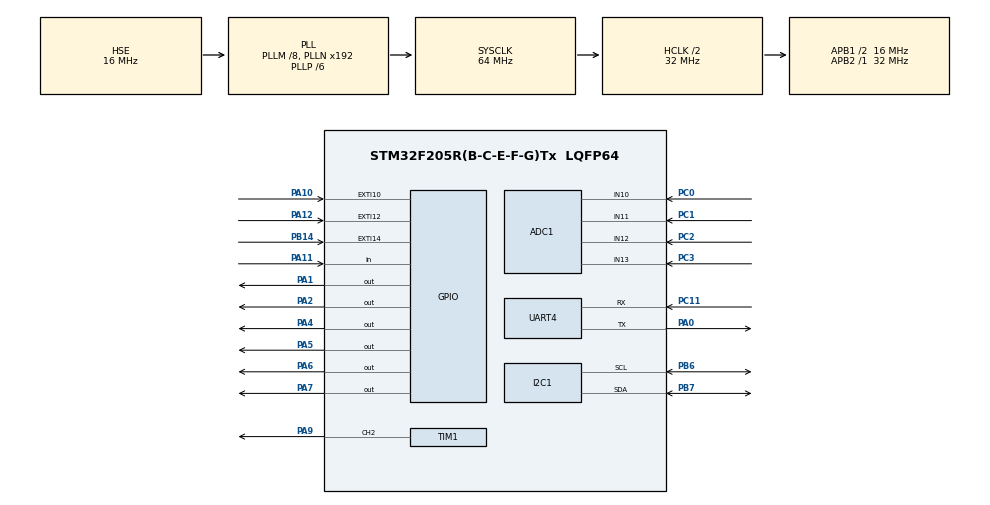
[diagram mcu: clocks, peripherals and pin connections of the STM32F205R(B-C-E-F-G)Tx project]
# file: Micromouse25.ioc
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ADC1.Channel-1\#ChannelRegularConversion=ADC_CHANNEL_10
ADC1.NbrOfConversionFlag=1
ADC1.Rank-1\#ChannelRegularConversion=1
ADC1.SamplingTime-1\#ChannelRegularConversion=ADC_SAMPLETIME_3CYCLES
ADC1.master=1
Mcu.Family=STM32F2
Mcu.Name=STM32F205R(B-C-E-F-G)Tx
Mcu.Package=LQFP64
NVIC.EXTI15_10_IRQn=true\:0\:0\:false\:false\:true\:true\:true\:true
NVIC.PriorityGroup=NVIC_PRIORITYGROUP_4
PA0-WKUP.Mode=Asynchronous
PA0-WKUP.Signal=UART4_TX
PA1.Signal=GPIO_Output
PA10.Signal=GPXTI10
PA11.Signal=GPIO_Input
PA12.Signal=GPXTI12
PA13.Mode=Serial_Wire
PA13.Signal=SYS_JTMS-SWDIO
PA14.Mode=Serial_Wire
PA14.Signal=SYS_JTCK-SWCLK
PA2.Signal=GPIO_Output
PA4.Signal=GPIO_Output
PA5.Signal=GPIO_Output
PA6.Signal=GPIO_Output
PA7.Signal=GPIO_Output
PA9.Signal=S_TIM1_CH2
PB14.Signal=GPXTI14
PB6.Mode=I2C
PB6.Signal=I2C1_SCL
PB7.Mode=I2C
PB7.Signal=I2C1_SDA
PC0.Signal=ADCx_IN10
PC1.Signal=ADCx_IN11
PC11.Mode=Asynchronous
PC11.Signal=UART4_RX
PC2.Signal=ADCx_IN12
PC3.Signal=ADCx_IN13
PH0-OSC_IN.Mode=HSE-External-Oscillator
PH0-OSC_IN.Signal=RCC_OSC_IN
PH1-OSC_OUT.Mode=HSE-External-Oscillator
PH1-OSC_OUT.Signal=RCC_OSC_OUT
ProjectManager.HeapSize=0x200
ProjectManager.StackSize=0x400
ProjectManager.TargetToolchain=STM32CubeIDE
RCC.48MHZClocksFreq_Value=96000000
RCC.AHBCLKDivider=RCC_SYSCLK_DIV2
RCC.AHBFreq_Value=32000000
RCC.APB1CLKDivider=RCC_HCLK_DIV2
RCC.APB1Freq_Value=16000000
RCC.APB1TimFreq_Value=32000000
RCC.APB2Freq_Value=32000000
RCC.APB2TimFreq_Value=32000000
RCC.CortexFreq_Value=32000000
RCC.HCLKFreq_Value=32000000
RCC.HSE_VALUE=16000000
RCC.HSI_VALUE=16000000
RCC.LSE_VALUE=32768
RCC.PLLM=8
RCC.PLLP=RCC_PLLP_DIV6
RCC.PLLSourceVirtual=RCC_PLLSOURCE_HSE
RCC.SYSCLKFreq_VALUE=64000000
RCC.SYSCLKSource=RCC_SYSCLKSOURCE_PLLCLK
RCC.VCOOutputFreq_Value=384000000
SH.ADCx_IN10.0=ADC1_IN10,IN10
SH.ADCx_IN11.0=ADC1_IN11,IN11
SH.ADCx_IN12.0=ADC1_IN12,IN12
SH.ADCx_IN13.0=ADC1_IN13,IN13
SH.S_TIM1_CH2.0=TIM1_CH2,PWM Generation2 CH2
TIM1.Channel-PWM\ Generation2\ CH2=TIM_CHANNEL_2
TIM1.Period=3199
UART4.VirtualMode=Asynchronous
VP_TIM1_VS_ClockSourceINT.Mode=Internal
board=custom

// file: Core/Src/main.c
/* USER CODE BEGIN Header */
/**
  ******************************************************************************
  * @file           : main.c
  * @brief          : Main program body
  ******************************************************************************
  * @attention
  *
  * Copyright (c) 2025 STMicroelectronics.
  * All rights reserved.
  *
  * This software is licensed under terms that can be found in the LICENSE file
  * in the root directory of this software component.
  * If no LICENSE file comes with this software, it is provided AS-IS.
  *
  ******************************************************************************
  */
/* USER CODE END Header */
#include "main.h"
#include "adc.h"
#include "i2c.h"
#include "tim.h"
#include "usart.h"
#include "gpio.h"

/* USER CODE BEGIN Includes */
#include "util.h"
#include "encoder.h"
/* USER CODE END Includes */

void SystemClock_Config(void);

int main(void)
{

  /* MCU Configuration--------------------------------------------------------*/

  /* Reset of all peripherals, Initializes the Flash interface and the Systick. */
  HAL_Init();

  /* Configure the system clock */
  SystemClock_Config();

  /* Initialize all configured peripherals */
  MX_GPIO_Init();
  MX_ADC1_Init();
  MX_I2C1_Init();
  MX_UART4_Init();
  MX_TIM1_Init();
  /* USER CODE BEGIN 2 */

  HAL_TIM_PWM_Start(&htim1, TIM_CHANNEL_2);
  /* USER CODE END 2 */

  /* Infinite loop */
  while (1)
  {

  }
}

void SystemClock_Config(void)
{
  RCC_OscInitTypeDef RCC_OscInitStruct = {0};
  RCC_ClkInitTypeDef RCC_ClkInitStruct = {0};

  /** Initializes the RCC Oscillators according to the specified parameters
  * in the RCC_OscInitTypeDef structure.
  */
  RCC_OscInitStruct.OscillatorType = RCC_OSCILLATORTYPE_HSE;
  RCC_OscInitStruct.HSEState = RCC_HSE_ON;
  RCC_OscInitStruct.PLL.PLLState = RCC_PLL_ON;
  RCC_OscInitStruct.PLL.PLLSource = RCC_PLLSOURCE_HSE;
  RCC_OscInitStruct.PLL.PLLM = 8;
  RCC_OscInitStruct.PLL.PLLN = 192;
  RCC_OscInitStruct.PLL.PLLP = RCC_PLLP_DIV6;
  RCC_OscInitStruct.PLL.PLLQ = 4;
  if (HAL_RCC_OscConfig(&RCC_OscInitStruct) != HAL_OK)
  {
    Error_Handler();
  }

  /** Initializes the CPU, AHB and APB buses clocks
  */
  RCC_ClkInitStruct.ClockType = RCC_CLOCKTYPE_HCLK|RCC_CLOCKTYPE_SYSCLK
                              |RCC_CLOCKTYPE_PCLK1|RCC_CLOCKTYPE_PCLK2;
  RCC_ClkInitStruct.SYSCLKSource = RCC_SYSCLKSOURCE_PLLCLK;
  RCC_ClkInitStruct.AHBCLKDivider = RCC_SYSCLK_DIV2;
  RCC_ClkInitStruct.APB1CLKDivider = RCC_HCLK_DIV2;
  RCC_ClkInitStruct.APB2CLKDivider = RCC_HCLK_DIV1;

  if (HAL_RCC_ClockConfig(&RCC_ClkInitStruct, FLASH_LATENCY_1) != HAL_OK)
  {
    Error_Handler();
  }
}

/* USER CODE BEGIN 4 */
void HAL_GPIO_EXTI_Callback(uint16_t GPIO_Pin)
{
  if(GPIO_Pin == Renca_pin || GPIO_Pin == Lenca_pin) {
    update_encoder(GPIO_Pin);
  }
}

/* USER CODE END 4 */

void Error_Handler(void)
{
  __disable_irq();
  while (1)
  {
  }
}
